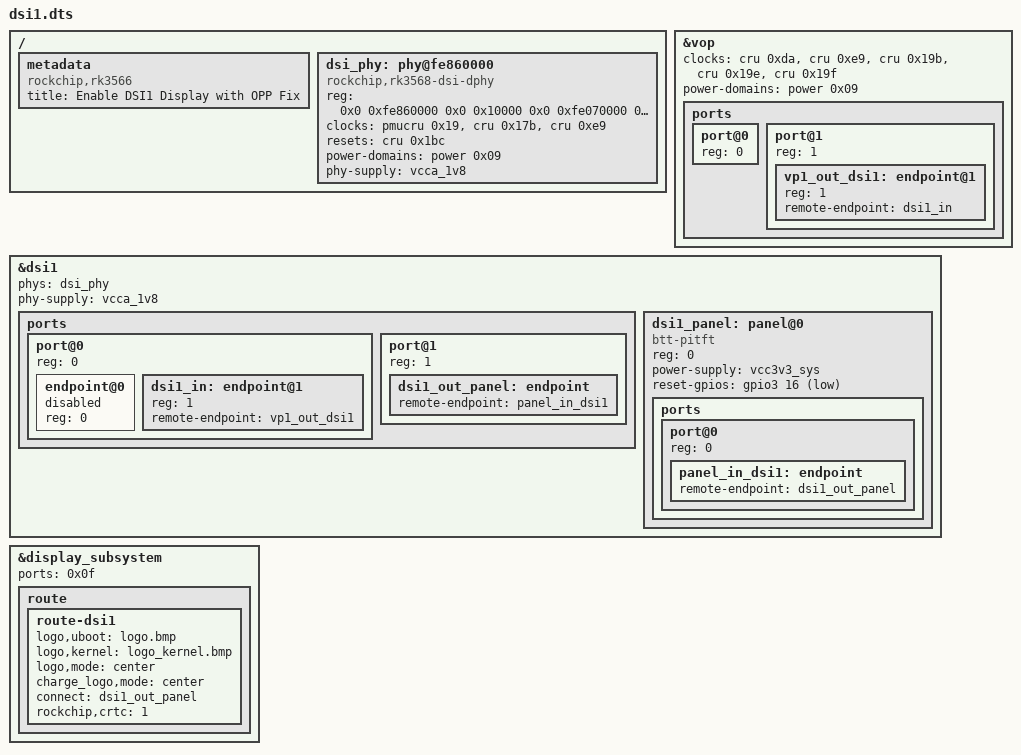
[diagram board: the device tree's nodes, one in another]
/dts-v1/;
/plugin/;

/ {
	metadata {
		title = "Enable DSI1 Display with OPP Fix";
		compatible = "rockchip,rk3566";
	};

	/* Fragment 0: Enable VOP with full clock configuration */
	fragment@0 {
		target = <&vop>;
		__overlay__ {
			status = "okay";
			clocks = <&cru 0xda>, <&cru 0xe9>, <&cru 0x19b>, <&cru 0x19e>, <&cru 0x19f>;  // HCLK_VOP, PCLK_VOP, ACLK_VOP, DCLK_VP0, DCLK_VP1
			clock-names = "hclk", "pclk", "aclk", "dclk_vp0", "dclk_vp1";
			power-domains = <&power 0x09>;  // PD_VOP1
			ports {
				#address-cells = <1>;
				#size-cells = <0>;

				port@0 {  // vp0, CRTC0
					reg = <0>;
					status = "okay";
				};

				port@1 {  // vp1, CRTC1
					reg = <1>;
					status = "okay";
					vp1_out_dsi1: endpoint@1 {
						reg = <1>;
						remote-endpoint = <&dsi1_in>;
					};
				};
			};
		};
	};

	/* Fragment 1: Enable and configure DSI1 */
	fragment@1 {
		target = <&dsi1>;
		__overlay__ {
			status = "okay";
			#address-cells = <1>;
			#size-cells = <0>;
			phys = <&dsi_phy>;
			phy-names = "dphy";
			phy-supply = <&vcca_1v8>;

			ports {
				#address-cells = <1>;
				#size-cells = <0>;

				port@0 {
					reg = <0>;
					endpoint@0 {
						reg = <0>;
						status = "disabled";
					};
					dsi1_in: endpoint@1 {
						reg = <1>;
						status = "okay";
						remote-endpoint = <&vp1_out_dsi1>;
					};
				};

				port@1 {
					reg = <1>;
					dsi1_out_panel: endpoint {
						remote-endpoint = <&panel_in_dsi1>;
					};
				};
			};

			dsi1_panel: panel@0 {
				status = "okay";
				compatible = "btt-pitft";
				reg = <0>;
				power-supply = <&vcc3v3_sys>;
				reset-gpios = <&gpio3 16 1>;
				ports {
					#address-cells = <1>;
					#size-cells = <0>;
					port@0 {
						reg = <0>;
						panel_in_dsi1: endpoint {
							remote-endpoint = <&dsi1_out_panel>;
						};
					};
				};
			};
		};
	};

	/* Fragment 2: Update display-subsystem */
	fragment@2 {
		target = <&display_subsystem>;
		__overlay__ {
			ports = <0x0f>;
			route {
				route-dsi1 {
					status = "okay";
					logo,uboot = "logo.bmp";
					logo,kernel = "logo_kernel.bmp";
					logo,mode = "center";
					charge_logo,mode = "center";
					connect = <&dsi1_out_panel>;
					rockchip,crtc = <1>;  // CRTC1 (vp1)
				};
			};
		};
	};

	/* Fragment 3: PHY (unchanged) */
	fragment@3 {
		target-path = "/";
		__overlay__ {
			dsi_phy: phy@fe860000 {
				compatible = "rockchip,rk3568-dsi-dphy", "rockchip,rk3568-video-phy";
				reg = <0x0 0xfe860000 0x0 0x10000 0x0 0xfe070000 0x0 0x10000>;
				reg-names = "phy", "host";
				clocks = <&pmucru 0x19>, <&cru 0x17b>, <&cru 0xe9>;
				clock-names = "ref", "pclk", "pclk_host";
				resets = <&cru 0x1bc>;
				reset-names = "apb";
				power-domains = <&power 0x09>;
				#phy-cells = <0>;
				status = "okay";
				phy-supply = <&vcca_1v8>;
			};
		};
	};
};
